BO_ 3 acclerations: 17 XXX
 SG_ like_acceleration1 : 32|12@1+ (1,0) [0|31] "" XXX
 SG_ like_acceleration2 : 68|12@1+ (1,0) [0|15] "" XXX

BO_ 35 NEW_MSG_23: 17 XXX

BO_ 46 WHEEL_SPEEDS: 17 XXX
 SG_ CYCLE_COUNT : 7|8@0+ (1,0) [0|255] "" XXX
 SG_ CHECKSUM : 15|8@0+ (1,0) [0|255] "" XXX
 SG_ COUNTER : 19|4@0+ (1,0) [0|15] "" XXX
 SG_ RL : 24|16@1+ (0.0198863636363636,-652) [0|65535] "km/h" XXX
 SG_ RR : 40|16@1+ (0.0198863636363636,-652) [0|65535] "km/h" XXX
 SG_ FL : 56|16@1+ (0.0198863636363636,-652) [0|65535] "km/h" XXX
 SG_ FR : 72|16@1+ (0.0198863636363636,-652) [0|65535] "km/h" XXX
 SG_ RR_STATE : 91|4@0+ (1,0) [0|15] "" XXX
 SG_ FL_STATE : 95|4@0+ (1,0) [0|15] "" XXX
 SG_ FR_STATE : 99|4@0+ (1,0) [0|15] "" XXX
 SG_ RL_STATE : 103|4@0+ (1,0) [0|15] "" XXX

BO_ 72 ACC: 17 SAS
 SG_ cycle_count M : 1|2@0+ (1,0) [0|63] "" XXX
 SG_ crc1 m1 : 8|8@1+ (1,0) [0|255] "" XXX
 SG_ cnt1 m1 : 16|4@1+ (1,0) [0|255] "" XXX
 SG_ always_0x9 m1 : 20|4@1+ (1,0) [0|15] "" XXX
 SG_ steering_angle_req m1 : 24|16@1+ (0.04395,-1098.75) [0|31] "" XXX
 SG_ steer_torque_req m1 : 40|16@1+ (0.006,-196.596) [0|255] "" XXX
 SG_ TJA_ready m1 : 56|8@1+ (1,0) [0|255] "" XXX
 SG_ assist_mode m1 : 64|2@1+ (1,0) [0|1] "" XXX
 SG_ wayback_en1_lane_keeping_trigger m1 : 71|6@0+ (1,0) [0|1] "" XXX
 SG_ lane_keeping_triggered m1 : 72|8@1+ (1,0) [0|255] "" XXX
 SG_ like_assist_torque_reserve m1 : 80|8@1+ (1,0) [0|255] "" XXX
 SG_ constants m1 : 88|26@1+ (1,0) [0|131071] "" XXX
 SG_ wayback_en_2 m1 : 114|2@1+ (1,0) [0|1] "" XXX
 SG_ steering_engaged m1 : 116|4@1+ (1,0) [0|255] "" XXX
 SG_ maybe_assist_force_enhance m1 : 120|8@1+ (1,0) [0|255] "" XXX
 SG_ maybe_assist_force_weaken m1 : 128|8@1+ (1,0) [0|255] "" XXX

BO_ 86 NEW_MSG_56: 17 XXX
 SG_ NEW_SIGNAL_1 : 32|2@1+ (1,0) [0|3] "" XXX

BO_ 117 NEW_MSG_75: 9 XXX
 SG_ NEW_SIGNAL_1 M : 0|1@0+ (1,0) [0|3] "" XXX
 SG_ engine_start m0 : 24|4@1+ (1,0) [0|15] "" XXX

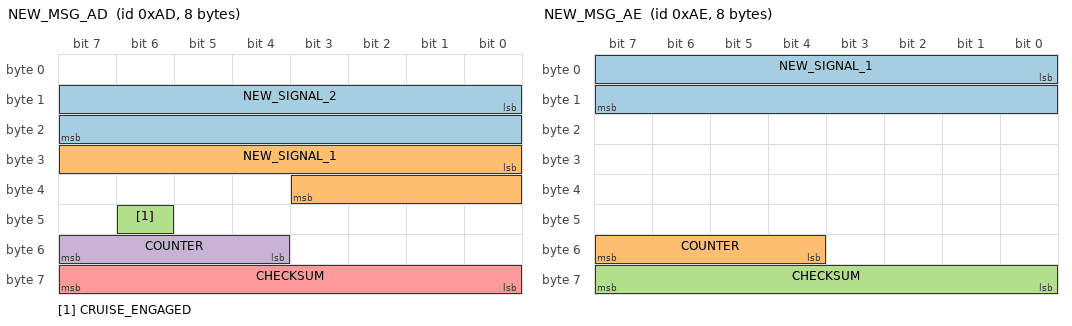
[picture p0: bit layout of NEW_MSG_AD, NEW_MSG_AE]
BO_ 173 NEW_MSG_AD: 8 XXX
 SG_ NEW_SIGNAL_2 : 8|16@1+ (1,0) [0|255] "" XXX
 SG_ NEW_SIGNAL_1 : 24|12@1+ (1,0) [0|255] "" XXX
 SG_ CRUISE_ENGAGED : 46|1@0+ (1,0) [0|1] "" XXX
 SG_ COUNTER : 55|4@0+ (1,0) [0|15] "" XXX
 SG_ CHECKSUM : 63|8@0+ (1,0) [0|255] "" XXX

BO_ 174 NEW_MSG_AE: 8 XXX
 SG_ NEW_SIGNAL_1 : 0|16@1+ (1,0) [0|65535] "" XXX
 SG_ COUNTER : 55|4@0+ (1,0) [0|15] "" XXX
 SG_ CHECKSUM : 63|8@0+ (1,0) [0|255] "" XXX

BO_ 225 NEW_MSG_E1: 8 SAS
 SG_ CHECKSUM : 7|8@0+ (1,0) [0|255] "" XXX
 SG_ COUNTER : 11|4@0+ (1,0) [0|15] "" XXX

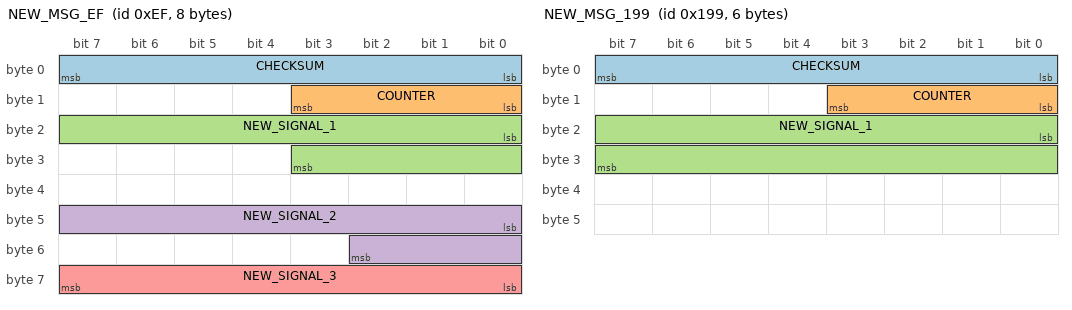
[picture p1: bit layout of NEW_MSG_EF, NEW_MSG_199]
BO_ 239 NEW_MSG_EF: 8 XXX
 SG_ CHECKSUM : 7|8@0+ (1,0) [0|255] "" XXX
 SG_ COUNTER : 11|4@0+ (1,0) [0|15] "" XXX
 SG_ NEW_SIGNAL_1 : 16|12@1+ (1,0) [0|1023] "" XXX
 SG_ NEW_SIGNAL_2 : 40|11@1+ (1,0) [0|255] "" XXX
 SG_ NEW_SIGNAL_3 : 63|8@0+ (1,0) [0|255] "" XXX

BO_ 315 NEW_MSG_13B: 8 SAS
 SG_ CHECKSUM : 7|8@0+ (1,0) [0|255] "" XXX
 SG_ COUNTER : 11|4@0+ (1,0) [0|15] "" XXX

BO_ 341 NEW_MSG_155: 8 XXX
 SG_ CHECKSUM : 7|8@0+ (1,0) [0|255] "" XXX
 SG_ COUNTER : 11|4@0+ (1,0) [0|15] "" XXX

BO_ 375 NEW_MSG_177: 8 SAS
 SG_ NEW_SIGNAL_1 : 61|2@0+ (1,0) [0|3] "" XXX

BO_ 409 NEW_MSG_199: 6 XXX
 SG_ CHECKSUM : 7|8@0+ (1,0) [0|255] "" XXX
 SG_ COUNTER : 11|4@0+ (1,0) [0|15] "" XXX
 SG_ NEW_SIGNAL_1 : 16|16@1+ (1,0) [0|65535] "" XXX

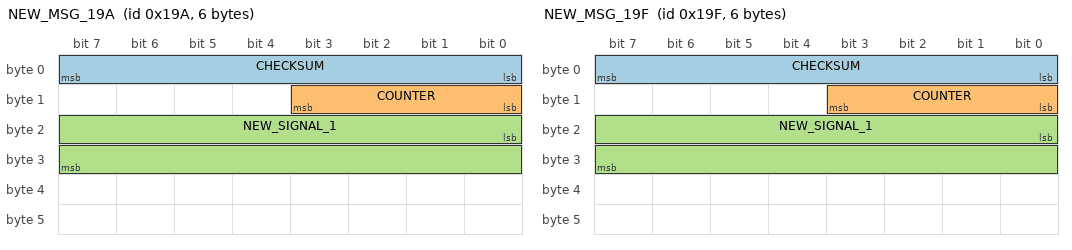
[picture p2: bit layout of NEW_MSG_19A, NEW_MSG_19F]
BO_ 410 NEW_MSG_19A: 6 XXX
 SG_ CHECKSUM : 7|8@0+ (1,0) [0|255] "" XXX
 SG_ COUNTER : 11|4@0+ (1,0) [0|15] "" XXX
 SG_ NEW_SIGNAL_1 : 16|16@1+ (1,0) [0|65535] "" XXX

BO_ 415 NEW_MSG_19F: 6 XXX
 SG_ CHECKSUM : 7|8@0+ (1,0) [0|255] "" XXX
 SG_ COUNTER : 11|4@0+ (1,0) [0|15] "" XXX
 SG_ NEW_SIGNAL_1 : 16|16@1+ (1,0) [0|65535] "" XXX

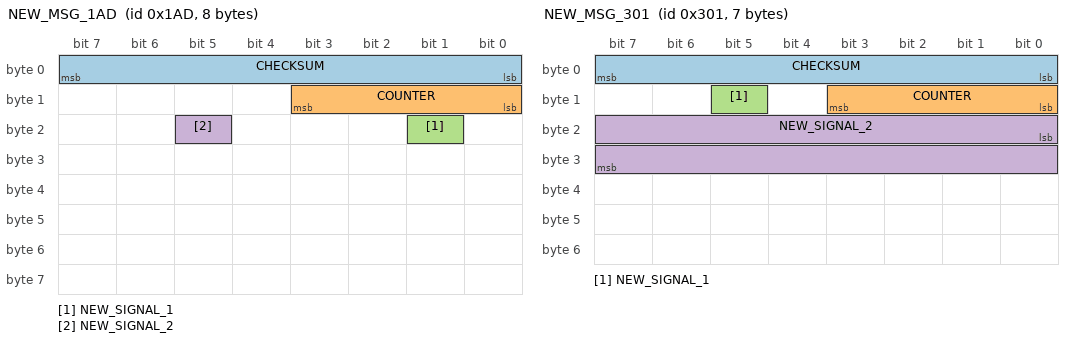
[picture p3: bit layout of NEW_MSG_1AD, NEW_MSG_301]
BO_ 429 NEW_MSG_1AD: 8 SAS
 SG_ CHECKSUM : 7|8@0+ (1,0) [0|255] "" XXX
 SG_ COUNTER : 11|4@0+ (1,0) [0|15] "" XXX
 SG_ NEW_SIGNAL_1 : 17|1@0+ (1,0) [0|1] "" XXX
 SG_ NEW_SIGNAL_2 : 21|1@0+ (1,0) [0|1] "" XXX

BO_ 494 CAN_BLINKER_STALK: 2 XXX
 SG_ STALK_RIGHT : 1|2@0+ (1,0) [0|3] "" XXX
 SG_ STALK_LEFT : 3|2@0+ (1,0) [0|3] "" XXX

BO_ 502 CAN_BLINKER_STATE: 2 XXX
 SG_ LEFT : 4|1@0+ (1,0) [0|1] "" XXX
 SG_ RIGHT : 5|1@0+ (1,0) [0|1] "" XXX

BO_ 553 NEW_MSG_229: 8 SAS
 SG_ CHECKSUM : 7|8@0+ (1,0) [0|255] "" XXX
 SG_ COUNTER : 11|4@0+ (1,0) [0|15] "" XXX

BO_ 630 NEW_MSG_276: 8 SAS

BO_ 769 NEW_MSG_301: 7 XXX
 SG_ CHECKSUM : 7|8@0+ (1,0) [0|255] "" XXX
 SG_ COUNTER : 11|4@0+ (1,0) [0|15] "" XXX
 SG_ NEW_SIGNAL_1 : 13|1@0+ (1,0) [0|1] "" XXX
 SG_ NEW_SIGNAL_2 : 16|16@1+ (1,0) [0|65535] "" XXX

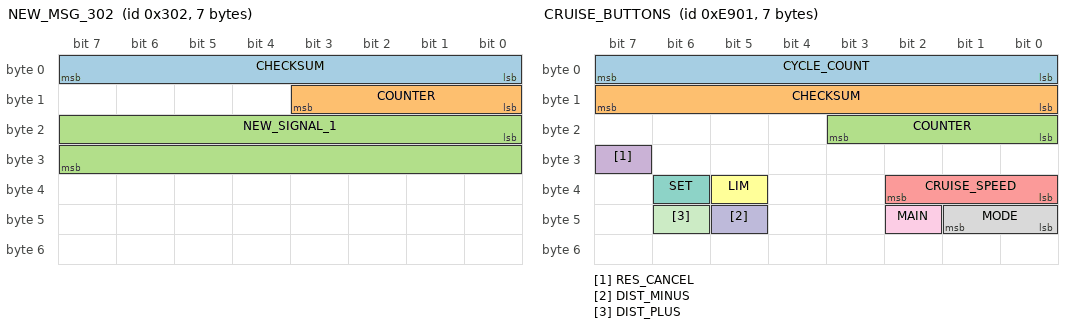
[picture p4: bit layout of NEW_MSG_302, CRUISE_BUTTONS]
BO_ 770 NEW_MSG_302: 7 XXX
 SG_ CHECKSUM : 7|8@0+ (1,0) [0|255] "" XXX
 SG_ COUNTER : 11|4@0+ (1,0) [0|15] "" XXX
 SG_ NEW_SIGNAL_1 : 16|16@1+ (1,0) [0|65535] "" XXX

BO_ 797 NEW_MSG_31D: 8 SAS

BO_ 855 NEW_MSG_357: 5 SAS

BO_ 886 NEW_MSG_376: 8 XXX
 SG_ CHECKSUM : 7|8@0+ (1,0) [0|255] "" XXX
 SG_ COUNTER : 11|4@0+ (1,0) [0|15] "" XXX

BO_ 6400 WHEEL_ODOMETRY: 17 XXX
 SG_ CYCLE_COUNT : 7|8@0+ (1,0) [0|255] "" XXX
 SG_ CHECKSUM : 15|8@0+ (1,0) [0|255] "" XXX
 SG_ COUNTER : 19|4@0+ (1,0) [0|15] "" XXX
 SG_ WHEEL_1 : 24|16@1+ (1,0) [0|65535] "" XXX
 SG_ WHEEL_2 : 48|16@1+ (1,0) [0|65535] "" XXX
 SG_ WHEEL_3 : 64|16@1+ (1,0) [0|65535] "" XXX
 SG_ WHEEL_4 : 88|16@1+ (1,0) [0|65535] "" XXX
 SG_ COUNTER_SOMETHING : 104|16@1+ (1,0) [0|65535] "" XXX

BO_ 6912 BRAKES: 17 XXX
 SG_ CYCLE_COUNT : 7|8@0+ (1,0) [0|255] "" XXX
 SG_ CHECKSUM : 15|8@0+ (1,0) [0|255] "" XXX
 SG_ COUNTER : 19|4@0+ (1,0) [0|15] "" XXX
 SG_ BRAKE_PRESSURE_1 : 24|16@1+ (1,0) [0|65535] "" XXX
 SG_ BRAKE_PRESSURE_2 : 40|16@1+ (1,0) [0|65535] "" XXX
 SG_ BRAKE_PRESSURE_3 : 56|16@1+ (1,0) [0|65535] "" XXX
 SG_ BRAKE_PRESSURE_4 : 72|16@1+ (1,0) [0|65535] "" XXX
 SG_ NEW_SIGNAL_1 : 91|1@0+ (1,0) [0|1] "" XXX
 SG_ NEW_SIGNAL_2 : 95|2@0+ (1,0) [0|3] "" XXX
 SG_ NEW_SIGNAL_5 : 97|2@0+ (1,0) [0|3] "" XXX
 SG_ NEW_SIGNAL_7 : 107|1@0+ (1,0) [0|1] "" XXX
 SG_ NEW_SIGNAL_3 : 111|2@0+ (1,0) [0|3] "" XXX
 SG_ NEW_SIGNAL_8 : 115|1@0+ (1,0) [0|1] "" XXX
 SG_ NEW_SIGNAL_4 : 119|2@0+ (1,0) [0|3] "" XXX
 SG_ NEW_SIGNAL_6 : 127|8@0+ (1,0) [0|255] "" XXX

BO_ 8192 NEW_MSG_2000: 17 XXX
 SG_ CYCLE_COUNT : 7|8@0+ (1,0) [0|255] "" XXX
 SG_ NEW_SIGNAL_1 : 20|12@1+ (1,0) [0|8191] "" XXX
 SG_ NEW_SIGNAL_2 : 32|12@1+ (1,0) [0|4095] "" XXX
 SG_ NEW_SIGNAL_3 : 44|12@1+ (1,0) [0|8191] "" XXX

BO_ 9728 NEW_MSG_2600: 17 XXX
 SG_ NEW_SIGNAL_1 : 32|16@1+ (1,0) [0|2047] "" XXX

BO_ 9984 STEERING_WHEEL_7: 17 XXX
 SG_ MULTIPLEXOR M : 8|1@0+ (1,0) [0|1] "" XXX
 SG_ NEW_SIGNAL_1 m0 : 103|8@0+ (1,0) [0|255] "" XXX
 SG_ NEW_SIGNAL_2 m0 : 111|8@0+ (1,0) [0|255] "" XXX
 SG_ CYCLE_COUNT : 7|8@0+ (1,0) [0|255] "" XXX

BO_ 9985 STEERING_WHEEL_4: 17 XXX
 SG_ CYCLE_COUNT : 7|8@0+ (1,0) [0|255] "" XXX
 SG_ CHECKSUM : 15|8@0+ (1,0) [0|255] "" XXX
 SG_ COUNTER : 19|4@0+ (1,0) [0|15] "" XXX
 SG_ STEERING_ANGLE : 24|16@1+ (0.04395,-1440.1536) [0|3] "" XXX
 SG_ COUNTER_SOMETHING : 72|12@1+ (1,0) [0|4095] "" XXX

BO_ 10241 GEARBOX_1: 17 XXX
 SG_ CYCLE_COUNT : 7|8@0+ (1,0) [0|255] "" XXX
 SG_ CHECKSUM : 15|8@0+ (1,0) [0|255] "" XXX
 SG_ COUNTER : 19|4@0+ (1,0) [0|15] "" XXX
 SG_ RPM : 50|14@1+ (1,0) [0|65535] "" XXX
 SG_ COUNTER_SOMETHING : 72|12@1+ (1,0) [0|65535] "" XXX
 SG_ TORQUE_REQUEST_MAYBE : 104|12@1+ (1,0) [0|65535] "" XXX

BO_ 10243 GEARBOX_2: 17 XXX
 SG_ CYCLE_COUNT : 7|8@0+ (1,0) [0|255] "" XXX
 SG_ CHECKSUM : 15|8@0+ (1,0) [0|255] "" XXX
 SG_ COUNTER : 19|4@0+ (1,0) [0|15] "" XXX
 SG_ GEAR : 27|4@0+ (1,0) [0|7] "" XXX
 SG_ OUTPUT_SPEED : 32|16@1+ (1,-2000) [0|255] "" XXX
 SG_ PARK_LOCKED : 49|1@0+ (1,0) [0|1] "" XXX

BO_ 10497 NEW_MSG_2901: 17 XXX
 SG_ CYCLE_COUNT : 7|8@0+ (1,0) [0|255] "" XXX
 SG_ CHECKSUM : 15|8@0+ (1,0) [0|255] "" XXX
 SG_ COUNTER : 19|4@0+ (1,0) [0|15] "" XXX
 SG_ NEW_SIGNAL_4 : 24|16@1+ (1,-32768) [0|65535] "" XXX
 SG_ NEW_SIGNAL_3 : 40|16@1+ (1,-32768) [0|65535] "" XXX
 SG_ NEW_SIGNAL_1 : 96|16@1+ (1,-32768) [0|65535] "" XXX
 SG_ NEW_SIGNAL_2 : 120|16@1+ (1,-32768) [0|65535] "" XXX

BO_ 10752 NEW_MSG_2A00: 17 XXX

BO_ 11009 BRAKE_PEDAL_1: 17 XXX
 SG_ CYCLE_COUNT : 7|8@0+ (1,0) [0|255] "" XXX
 SG_ CHECKSUM : 15|8@0+ (1,0) [0|255] "" XXX
 SG_ COUNTER : 19|4@0+ (1,0) [0|15] "" XXX
 SG_ BRAKE_RELEASED_1 : 36|1@0+ (1,0) [0|1] "" XXX
 SG_ BRAKE_RELEASED_2 : 38|1@0+ (1,0) [0|1] "" XXX
 SG_ BRAKE_RELEASED_3 : 39|1@0+ (1,0) [0|1] "" XXX
 SG_ EPB_ENGAGE_SOMETHING : 41|2@0+ (1,0) [0|3] "" XXX
 SG_ EPB_RELEASE_SOMETHING : 43|2@0+ (1,0) [0|3] "" XXX
 SG_ NEW_SIGNAL_1 : 45|2@0+ (1,0) [0|3] "" XXX
 SG_ BRAKE_PRESSURE_SOMETHING : 79|8@0+ (1,0) [0|255] "" XXX
 SG_ BRAKE_PEDAL_POSITION_INV : 88|16@1+ (1,0) [0|65535] "" XXX
 SG_ BRAKE_PEDAL_POSITION_1 : 104|12@1+ (1,0) [0|4095] "" XXX
 SG_ BRAKE_PEDAL_POSITION_2 : 116|12@1+ (1,0) [0|15] "" XXX

BO_ 11011 BRAKE_PEDAL_2: 17 XXX
 SG_ CYCLE_COUNT : 7|8@0+ (1,0) [0|255] "" XXX
 SG_ CHECKSUM : 15|8@0+ (1,0) [0|255] "" XXX
 SG_ COUNTER : 19|4@0+ (1,0) [0|15] "" XXX
 SG_ BRAKE_PEDAL_POSITION_INV_1 : 24|16@1+ (1,0) [0|65535] "" XXX
 SG_ BRAKE_PEDAL_POSITION_INV_2 : 48|16@1+ (1,0) [0|65535] "" XXX
 SG_ BRAKE_PEDAL_POSITION_3 : 71|8@0+ (1,0) [0|255] "" XXX

BO_ 12033 BRAKE_PEDAL_3: 17 XXX
 SG_ CYCLE_COUNT : 7|8@0+ (1,0) [0|255] "" XXX
 SG_ CHECKSUM : 15|8@0+ (1,0) [0|255] "" XXX
 SG_ COUNTER : 19|4@0+ (1,0) [0|15] "" XXX
 SG_ BRAKE_PRESSED_3 : 66|3@0+ (1,0) [0|7] "" XXX
 SG_ NEW_SIGNAL_1 : 67|1@0+ (1,0) [0|1] "" XXX
 SG_ STANDSTILL_SOMETHING : 68|1@0+ (1,0) [0|1] "" XXX
 SG_ NEW_SIGNAL_2 : 71|1@0+ (1,0) [0|1] "" XXX
 SG_ COUNTER_2 : 83|4@0+ (1,0) [0|15] "" XXX
 SG_ BRAKE_PRESSED_2 : 112|1@0+ (1,0) [0|1] "" XXX
 SG_ BRAKE_RESSED_1 : 114|1@0+ (1,0) [0|1] "" XXX
 SG_ BRAKE_PRESSED_4 : 133|1@0+ (1,0) [0|1] "" XXX

BO_ 12544 STEERING_WHEEL_5: 17 XXX
 SG_ CYCLE_COUNT : 7|8@0+ (1,0) [0|255] "" XXX
 SG_ CHECKSUM : 15|8@0+ (1,0) [0|255] "" XXX
 SG_ COUNTER : 19|4@0+ (1,0) [0|15] "" XXX
 SG_ STEERING_TORQUE_1 : 24|12@1+ (1,-2000) [0|255] "" XXX
 SG_ NEW_SIGNAL_2 : 72|12@1+ (1,0) [0|65535] "" XXX
 SG_ STEERING_TORQUE_2 : 88|12@1+ (1,-2000) [0|4095] "" XXX
 SG_ NEW_SIGNAL_1 : 107|4@0+ (1,0) [0|15] "" XXX

BO_ 12545 STEERING_WHEEL_6: 17 XXX
 SG_ CYCLE_COUNT : 7|8@0+ (1,0) [0|255] "" XXX
 SG_ CHECKSUM : 15|8@0+ (1,0) [0|255] "" XXX
 SG_ COUNTER : 19|4@0+ (1,0) [0|15] "" XXX
 SG_ STEERING_RATE_SOMETHING : 63|8@0+ (1,0) [0|255] "" XXX

BO_ 13056 STEERING_WHEEL_3: 17 XXX
 SG_ CYCLE_COUNT : 7|8@0+ (1,0) [0|255] "" XXX
 SG_ CHECKSUM : 15|8@0+ (1,0) [0|255] "" XXX
 SG_ COUNTER : 19|4@0+ (1,0) [0|15] "" XXX
 SG_ STEERING_ANGLE : 24|16@1+ (0.04395,-1440.1536) [0|65535] "" XXX
 SG_ NEW_SIGNAL_2 : 47|8@0+ (1,0) [0|255] "" XXX
 SG_ NEW_SIGNAL_1 : 55|8@0+ (1,0) [0|255] "" XXX
 SG_ NEW_SIGNAL_3 : 69|2@0+ (1,0) [0|3] "" XXX
 SG_ STEERING_TORQUE_EPS : 88|12@1+ (1,-1000) [0|4095] "" XXX

BO_ 14080 SPEED: 17 XXX
 SG_ CYCLE_COUNT : 0|8@1+ (1,0) [0|3] "" XXX
 SG_ VEHICLE_SPEED : 24|16@1+ (0.015625,0) [0|65535] "" XXX
 SG_ DRIVING_STATUS : 44|2@1+ (1,0) [0|7] "" XXX

BO_ 14337 KINEMATICS_1: 17 XXX
 SG_ CYCLE_COUNT : 7|8@0+ (1,0) [0|255] "" XXX
 SG_ CHECKSUM : 15|8@0+ (1,0) [0|255] "" XXX
 SG_ COUNTER : 19|4@0+ (1,0) [0|15] "" XXX
 SG_ PITCH : 24|12@1+ (1,0) [0|65535] "" XXX
 SG_ ROLL : 40|12@1+ (1,0) [0|65535] "" XXX
 SG_ Z_RATE_MAYBE : 56|12@1+ (1,0) [0|65535] "" XXX
 SG_ COUNTER_SOMETHING : 72|12@1+ (1,0) [0|65535] "" XXX
 SG_ YAW_RATE : 88|16@1+ (1,-32768) [0|65535] "" XXX

BO_ 14338 KINEMATICS_2: 17 XXX
 SG_ CYCLE_COUNT : 7|8@0+ (1,0) [0|255] "" XXX
 SG_ CHECKSUM : 79|8@0+ (1,0) [0|255] "" XXX
 SG_ COUNTER : 83|4@0+ (1,0) [0|15] "" XXX
 SG_ YAW_RATE : 88|16@1+ (1,-32768) [0|65535] "" XXX

BO_ 14593 KINEMATICS_3: 17 XXX
 SG_ CYCLE_COUNT : 7|8@0+ (1,0) [0|255] "" XXX
 SG_ CHECKSUM : 15|8@0+ (1,0) [0|255] "" XXX
 SG_ COUNTER : 19|4@0+ (1,0) [0|15] "" XXX
 SG_ YAW_RATE : 24|16@1+ (1,-32768) [0|65535] "" XXX

BO_ 14594 KINEMATICS_4: 17 XXX
 SG_ CYCLE_COUNT : 7|8@0+ (1,0) [0|255] "" XXX
 SG_ CHECKSUM : 15|8@0+ (1,0) [0|255] "" XXX
 SG_ COUNTER : 19|4@0+ (1,0) [0|15] "" XXX
 SG_ ACCELERATION : 24|16@1+ (0.0025,-81.25) [0|65535] "" XXX
 SG_ SPEED : 40|16@1+ (1,0) [0|65535] "" XXX

BO_ 14595 KINEMATICS_5: 17 XXX
 SG_ CYCLE_COUNT : 7|8@0+ (1,0) [0|255] "" XXX
 SG_ CHECKSUM : 15|8@0+ (1,0) [0|255] "" XXX
 SG_ COUNTER : 19|4@0+ (1,0) [0|15] "" XXX
 SG_ YAW_RATE : 24|16@1+ (1,-32768) [0|65535] "" XXX

BO_ 14849 NEW_MSG_3A01: 17 XXX
 SG_ VALID M : 22|1@0+ (1,0) [0|1] "" XXX
 SG_ COUNTER m1 : 19|4@0+ (1,0) [0|15] "" XXX
 SG_ CYCLE_COUNT : 7|8@0+ (1,0) [0|255] "" XXX
 SG_ CHECKSUM : 15|8@0+ (1,0) [0|255] "" XXX

BO_ 14850 NEW_MSG_3A02: 17 XXX
 SG_ CYCLE_COUNT : 7|8@0+ (1,0) [0|255] "" XXX
 SG_ CHECKSUM : 15|8@0+ (1,0) [0|255] "" XXX
 SG_ COUNTER : 19|4@0+ (1,0) [0|15] "" XXX

BO_ 14851 CRUISE_STATE: 17 XXX
 SG_ CYCLE_COUNT : 7|8@0+ (1,0) [0|255] "" XXX
 SG_ CHECKSUM : 15|8@0+ (1,0) [0|255] "" XXX
 SG_ COUNTER : 19|4@0+ (1,0) [0|15] "" XXX
 SG_ SET_ME_0xFA : 39|8@0+ (1,0) [0|255] "" XXX
 SG_ ACCELERATION_REQUEST_MAYBE : 40|16@1+ (0.0025,-81.25) [0|65535] "" XXX
 SG_ CRUISE_ENGAGED_1 : 59|1@0+ (1,0) [0|1] "" XXX
 SG_ CRUISE_ENGAGED_2 : 61|1@0+ (1,0) [0|1] "" XXX
 SG_ CRUISE_ENGAGED_3 : 67|2@0+ (1,0) [0|3] "" XXX
 SG_ SET_ME_0xFFFF : 72|16@1+ (1,0) [0|65535] "" XXX
 SG_ NEW_SIGNAL_2 : 88|11@1+ (1,0) [0|255] "" XXX
 SG_ SET_ME_0xFFFFFFFF : 104|32@1+ (1,0) [0|4294967295] "" XXX

BO_ 15104 STEERING_WHEEL_1: 17 XXX
 SG_ CYCLE_COUNT : 7|8@0+ (1,0) [0|255] "" XXX
 SG_ CHECKSUM : 15|8@0+ (1,0) [0|255] "" XXX
 SG_ COUNTER : 19|4@0+ (1,0) [0|15] "" XXX
 SG_ STEERING_ANGLE : 24|16@1+ (0.04395,-1440.1536) [0|65535] "" XXX

BO_ 15105 STEERING_WHEEL_2: 17 XXX
 SG_ CYCLE_COUNT : 7|8@0+ (1,0) [0|255] "" XXX
 SG_ STEERING_ANGLE_1 : 16|16@1+ (0.04395,-1098.75) [0|65535] "" XXX
 SG_ STEER_TORQUE_SOMETHING : 32|12@1+ (1,-2046) [0|65535] "" XXX
 SG_ NEW_SIGNAL_2 : 54|1@0+ (1,0) [0|1] "" XXX
 SG_ HANDS_OFF_WHEEL : 55|1@0+ (1,0) [0|1] "" XXX
 SG_ STEERING_ANGLE_2 : 88|16@1+ (0.04395,-1098.75) [0|65535] "" XXX
 SG_ NEW_SIGNAL_1 : 105|2@0+ (1,0) [0|3] "" XXX

BO_ 17408 EPS_CONTROL: 17 XXX
 SG_ CYCLE_COUNT : 7|8@0+ (1,0) [0|255] "" XXX
 SG_ CHECKSUM_1 : 15|8@0+ (1,0) [0|255] "" XXX
 SG_ COUNTER_1 : 19|4@0+ (1,0) [0|15] "" XXX
 SG_ SET_ME_0xF_1 : 23|4@0+ (1,0) [0|15] "" XXX
 SG_ SET_ME_0xD0 : 31|8@0+ (1,0) [0|255] "" XXX
 SG_ SET_ME_0xE7 : 39|8@0+ (1,0) [0|255] "" XXX
 SG_ NEW_SIGNAL_2 : 47|8@0+ (1,0) [0|255] "" XXX
 SG_ NEW_SIGNAL_1 : 48|8@1+ (1,0) [0|255] "" XXX
 SG_ NEW_SIGNAL_7 : 59|4@0+ (1,0) [0|7] "" XXX
 SG_ TORQUE_MODE : 67|4@0+ (1,0) [0|15] "" XXX
 SG_ TORQUE_REQUEST_1 : 68|1@0+ (1,0) [0|1] "" XXX
 SG_ CHECKSUM_2 : 79|8@0+ (1,0) [0|255] "" XXX
 SG_ COUNTER_2 : 83|4@0+ (1,0) [0|15] "" XXX
 SG_ SET_ME_0xF_2 : 87|4@0+ (1,0) [0|15] "" XXX
 SG_ TORQUE : 88|12@1+ (0.005,-10) [0|4095] "Nm" XXX
 SG_ TORQUE_MODE_CPY : 103|4@0+ (1,0) [0|15] "" XXX
 SG_ SET_ME_0xFF_1 : 111|8@0+ (1,0) [0|255] "" XXX
 SG_ SET_ME_0xFF_2 : 119|8@0+ (1,0) [0|255] "" XXX
 SG_ SET_ME_0xF_3 : 123|4@0+ (1,0) [0|15] "" XXX
 SG_ TORQUE_REQUEST_2 : 125|2@0+ (1,0) [0|3] "" XXX
 SG_ LKA_STATE : 131|4@0+ (1,0) [0|255] "" XXX
 SG_ TORQUE_REQUEST_3 : 132|1@0+ (1,0) [0|1] "" XXX

BO_ 17409 NEW_MSG_4401: 17 XXX
 SG_ CYCLE_COUNT : 7|8@0+ (1,0) [0|255] "" XXX
 SG_ NEW_SIGNAL_1 : 63|4@0+ (1,0) [0|15] "" XXX
 SG_ NEW_SIGNAL_2 : 71|8@0+ (1,0) [0|255] "" XXX

BO_ 17410 NEW_MSG_4402: 17 XXX
 SG_ NEW_SIGNAL_1 : 135|8@0+ (1,0) [0|255] "" XXX

BO_ 17664 NEW_MSG_4500: 17 XXX
 SG_ NEW_SIGNAL_3 : 24|16@1+ (1,-32768) [0|65535] "" XXX
 SG_ NEW_SIGNAL_2 : 56|16@1+ (1,-32768) [0|65535] "" XXX
 SG_ NEW_SIGNAL_1 : 72|16@1+ (1,-32768) [0|511] "" XXX

BO_ 17923 NEW_MSG_4603: 17 XXX
 SG_ CYCLE_COUNT : 7|8@0+ (1,0) [0|255] "" XXX
 SG_ CHECKSUM : 15|8@0+ (1,0) [0|255] "" XXX
 SG_ COUNTER : 19|4@0+ (1,0) [0|15] "" XXX
 SG_ CRUISE_STATE_RELATED : 31|8@0+ (1,0) [0|255] "" XXX

BO_ 18432 CRUISE_STATE_2: 17 SAS
 SG_ CYCLE_COUNT : 7|8@0+ (1,0) [0|255] "" XXX
 SG_ CHECKSUM_1 : 15|8@0+ (1,0) [0|255] "" XXX
 SG_ COUNTER_1 : 19|4@0+ (1,0) [0|15] "" XXX
 SG_ BRAKE_REQUEST : 24|16@1+ (1,-32000) [0|65535] "" XXX
 SG_ SET_ME_0x4 : 43|4@0+ (1,0) [0|15] "" XXX
 SG_ BRAKE_MODE : 45|2@0+ (1,0) [0|3] "" XXX
 SG_ SET_ME_0xD8 : 55|8@0+ (1,0) [0|255] "" XXX
 SG_ SET_ME_0xF0 : 63|8@0+ (1,0) [0|255] "" XXX
 SG_ SET_ME_0x20 : 71|8@0+ (1,0) [0|255] "" XXX
 SG_ CHECKSUM_2 : 79|8@0+ (1,0) [0|255] "" XXX
 SG_ COUNTER_2 : 83|4@0+ (1,0) [0|15] "" XXX
 SG_ SET_ME_0xEC : 95|8@0+ (1,0) [0|255] "" XXX
 SG_ SET_ME_0xFFFFFFFF : 111|32@0+ (1,0) [0|4294967295] "" XXX

BO_ 18433 STEER_REQUEST: 17 SAS
 SG_ CYCLE_COUNT : 7|8@0+ (1,0) [0|255] "" XXX
 SG_ CHECKSUM : 15|8@0+ (1,0) [0|255] "" XXX
 SG_ COUNTER : 19|4@0+ (1,0) [0|15] "" XXX
 SG_ SET_ME_0x9 : 23|4@0+ (1,0) [0|15] "" XXX
 SG_ STEER_ANGLE_REQUEST : 24|16@1+ (0.04395,-1098.75) [0|65535] "" XXX
 SG_ STEER_TORQUE_REQUEST : 40|16@1+ (0.006,-196.596) [0|65535] "" XXX
 SG_ ASSIST_MODE : 65|2@0+ (1,0) [0|3] "" XXX
 SG_ REVERSING_ASSIST : 70|5@0+ (1,0) [0|31] "" XXX
 SG_ ASSIST_TORQUE : 87|8@0+ (1,0) [0|255] "" XXX
 SG_ SET_ME_0xFE : 95|8@0+ (1,0) [0|255] "" XXX
 SG_ SET_ME_0x17 : 103|8@0+ (1,0) [0|255] "" XXX
 SG_ SET_ME_0xFF : 111|8@0+ (1,0) [0|255] "" XXX
 SG_ SET_ME_0x3 : 112|2@1+ (1,0) [0|3] "" XXX
 SG_ ACTIVE : 116|4@1+ (1,0) [0|15] "" XXX
 SG_ SET_ME_0xA2 : 127|8@0+ (1,0) [0|255] "" XXX
 SG_ SET_ME_0xFA : 135|8@0+ (1,0) [0|255] "" XXX

BO_ 18434 NEW_MSG_4802: 17 XXX
 SG_ CYCLE_COUNT : 7|8@0+ (1,0) [0|255] "" XXX
 SG_ CHECKSUM : 15|8@0+ (1,0) [0|255] "" XXX
 SG_ COUNTER : 19|4@0+ (1,0) [0|15] "" XXX

BO_ 23809 SET_SPEED: 9 SAS
 SG_ CYCLE_COUNT : 7|8@0+ (1,0) [0|255] "" XXX
 SG_ CHECKSUM : 15|8@0+ (1,0) [0|255] "" XXX
 SG_ COUNTER : 19|4@0+ (1,0) [0|15] "" XXX
 SG_ DISTANCE_SETTING : 35|3@0+ (1,0) [0|7] "" XXX
 SG_ SET_SPEED : 47|8@0+ (1,0) [0|255] "km/h" XXX

BO_ 59649 CRUISE_BUTTONS: 7 XXX
 SG_ CYCLE_COUNT : 7|8@0+ (1,0) [0|255] "" XXX
 SG_ CHECKSUM : 15|8@0+ (1,0) [0|255] "" XXX
 SG_ COUNTER : 19|4@0+ (1,0) [0|15] "" XXX
 SG_ RES_CANCEL : 31|1@0+ (1,0) [0|1] "" XXX
 SG_ CRUISE_SPEED : 34|3@0+ (1,0) [0|7] "" XXX
 SG_ LIM : 37|1@0+ (1,0) [0|1] "" XXX
 SG_ SET : 38|1@0+ (1,0) [0|1] "" XXX
 SG_ MODE : 41|2@0+ (1,0) [0|3] "" XXX
 SG_ MAIN : 42|1@0+ (1,0) [0|1] "" XXX
 SG_ DIST_MINUS : 45|1@0+ (1,0) [0|1] "" XXX
 SG_ DIST_PLUS : 46|1@0+ (1,0) [0|1] "" XXX

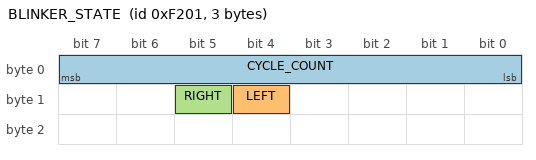
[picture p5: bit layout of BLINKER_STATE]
BO_ 61953 BLINKER_STATE: 3 XXX
 SG_ CYCLE_COUNT : 7|8@0+ (1,0) [0|255] "" XXX
 SG_ LEFT : 12|1@0+ (1,0) [0|1] "" XXX
 SG_ RIGHT : 13|1@0+ (1,0) [0|1] "" XXX

CM_ SG_ 12033 BRAKE_RESSED_1 "This seems to be the most sensitive brake pressed singal";
CM_ SG_ 14851 CRUISE_ENGAGED_2 "Pre-enable maybe";
CM_ SG_ 14851 CRUISE_ENGAGED_3 "Inverse of CRUISE_ENGAGED_1, also 3 at standstill";
CM_ SG_ 14851 NEW_SIGNAL_2 "Seems to drop when in turns";
CM_ SG_ 17408 NEW_SIGNAL_2 "0 when active, 0xFE most of the time otherwise";
CM_ SG_ 17408 NEW_SIGNAL_1 "0xFE most of the time";
CM_ SG_ 17408 TORQUE_MODE "2 when active, msotly 14 otherise";
CM_ SG_ 17408 TORQUE_MODE_CPY "mirror of TORQUE_MODE";
CM_ SG_ 17408 LKA_STATE "Ramp from 0-14 on engage/disengage. 5-9 otherwise";
CM_ SG_ 17408 TORQUE_REQUEST_3 "Only 1 while not ramping up/down";
CM_ SG_ 18432 BRAKE_MODE "Switch from regen to friction brakes maybe";
CM_ SG_ 23809 SET_SPEED "Signal seems to glitch sometimes";
VAL_ 117 engine_start 0 "stop" 1 "starting" 2 "running" 3 "off";
VAL_ 494 STALK_RIGHT 0 "NONE" 1 "HALF" 2 "FULL";
VAL_ 494 STALK_LEFT 0 "NONE" 1 "HALF" 2 "FULL";
VAL_ 10243 GEAR 2 "N" 4 "D" 5 "R";
VAL_ 17408 TORQUE_REQUEST_2 1 "INACTIVE" 2 "ACTIVE";
VAL_ 18433 ACTIVE 1 "INACTIVE" 2 "ACTIVE";
VAL_ 59649 CRUISE_SPEED 0 "NONE" 1 "UP_1" 2 "UP_10" 5 "DOWN_1" 6 "DOWN_10";
